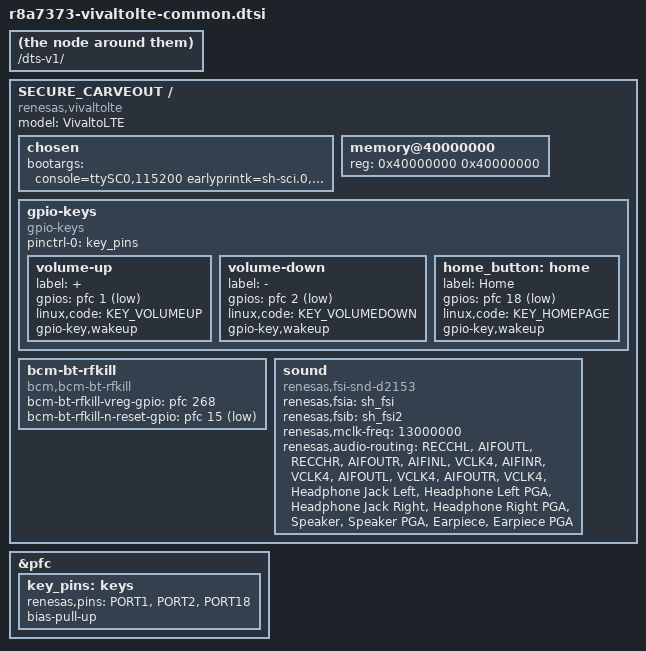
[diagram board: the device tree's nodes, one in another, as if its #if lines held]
/******************************************************************************/
/*                                                                            */
/* Copyright 2014 Broadcom Corporation                                        */
/*                                                                            */
/* Unless you and Broadcom execute a separate written software license        */
/* agreement governing use of this software, this software is licensed        */
/* to you under the terms of the GNU General Public License version 2         */
/* (the GPL), available at                                                    */
/*                                                                            */
/* http://www.broadcom.com/licenses/GPLv2.php                                 */
/*                                                                            */
/* with the following added to such license:                                  */
/*                                                                            */
/* As a special exception, the copyright holders of this software give        */
/* you permission to link this software with independent modules, and         */
/* to copy and distribute the resulting executable under terms of your        */
/* choice, provided that you also meet, for each linked independent           */
/* module, the terms and conditions of the license of that module.            */
/* An independent module is a module which is not derived from this           */
/* software. The special exception does not apply to any modifications        */
/* of the software.                                                           */
/*                                                                            */
/* Notwithstanding the above, under no circumstances may you combine          */
/* this software in any way with any other Broadcom software provided         */
/* under a license other than the GPL, without Broadcom's express             */
/* prior written consent.                                                     */
/*                                                                            */
/******************************************************************************/

/dts-v1/;
#ifdef SECURE_CARVEOUT	// Allow secure variant to insert memreserve, normally do nothing.
SECURE_CARVEOUT
#endif
#include "r8a7373.dtsi"
#include "rmobile-common.dtsi"
#include <dt-bindings/gpio/gpio.h>
#include <dt-bindings/input/input.h>

/{
	model = "VivaltoLTE";
	compatible = "renesas,vivaltolte", "renesas,r8a7373";

	chosen {
		bootargs = "console=ttySC0,115200 earlyprintk=sh-sci.0,115200 ignore_loglevel";
	};

	memory@40000000 {
		device_type = "memory";
		reg = <0x40000000 0x40000000>;
	};

	gpio-keys {
		compatible = "gpio-keys";
		#address-cells = <0>;
		#size-cells = <0>;
		pinctrl-names = "default";
		pinctrl-0 = <&key_pins>;

		volume-up {
			label = "+";
			gpios = <&pfc 1 GPIO_ACTIVE_LOW>;
			linux,code = <KEY_VOLUMEUP>;
			gpio-key,wakeup;
		};

		volume-down {
			label = "-";
			gpios = <&pfc 2 GPIO_ACTIVE_LOW>;
			linux,code = <KEY_VOLUMEDOWN>;
			gpio-key,wakeup;
		};

		/* Code may be changed to KEY_HOME by setup-u2gpio_key.c */
		home_button: home {
			label = "Home";
			gpios = <&pfc 18 GPIO_ACTIVE_LOW>;
			linux,code = <KEY_HOMEPAGE>;
			gpio-key,wakeup;
		};
	};

	bcm-bt-rfkill {
		compatible = "bcm,bcm-bt-rfkill";
		bcm-bt-rfkill-vreg-gpio = <&pfc 268 GPIO_ACTIVE_HIGH>;
		bcm-bt-rfkill-n-reset-gpio = <&pfc 15 GPIO_ACTIVE_LOW>;
	};

	sound {
		compatible = "renesas,fsi-snd-d2153";
		renesas,fsia = <&sh_fsi>;
		renesas,fsib = <&sh_fsi2>;
		renesas,mclk-freq = <13000000>;
		renesas,audio-routing =
			"RECCHL", "AIFOUTL",
			"RECCHR", "AIFOUTR",
			"AIFINL", "VCLK4",
			"AIFINR", "VCLK4",
			"AIFOUTL", "VCLK4",
			"AIFOUTR", "VCLK4",
			"Headphone Jack Left", "Headphone Left PGA",
			"Headphone Jack Right", "Headphone Right PGA",
			"Speaker", "Speaker PGA",
			"Earpiece", "Earpiece PGA";
	};
};

&pfc {
	key_pins: keys {
		renesas,pins = "PORT1", "PORT2", "PORT18";
		bias-pull-up;
	};
};
